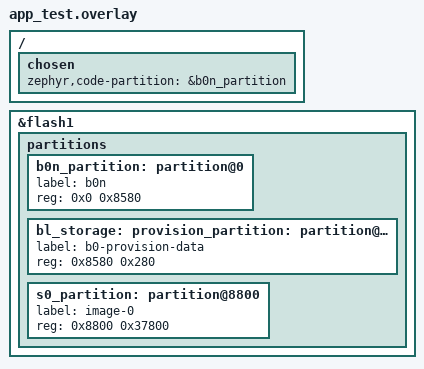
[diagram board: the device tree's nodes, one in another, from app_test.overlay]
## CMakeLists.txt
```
#
# Copyright (c) 2020 Nordic Semiconductor ASA
#
# SPDX-License-Identifier: LicenseRef-Nordic-5-Clause
#

cmake_minimum_required(VERSION 3.20.0)

find_package(Zephyr REQUIRED HINTS $ENV{ZEPHYR_BASE})
project(netboot)

zephyr_library_sources(src/main.c)
```

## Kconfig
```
#
# Copyright (c) 2026 Nordic Semiconductor ASA
#
# SPDX-License-Identifier: LicenseRef-Nordic-5-Clause
#

# minimal-size.conf disables logging, so the logging options are defaults that apply only
# when LOG is enabled.
if LOG

choice LOG_MODE
	depends on !LOG_FRONTEND_ONLY
	default LOG_MODE_MINIMAL
endchoice

configdefault LOG_DEFAULT_LEVEL
	default 0

if SECURE_BOOT_VALIDATION

choice SECURE_BOOT_VALIDATION_LOG_LEVEL_CHOICE
	default SECURE_BOOT_VALIDATION_LOG_LEVEL_INF
endchoice

endif # SECURE_BOOT_VALIDATION

endif # LOG

source "Kconfig.zephyr"
```

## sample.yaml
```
sample:
  name: Network core bootloader sample
  description: Network core bootloader sample for nRF5340
tests:
  sample.nrf5340.netboot:
    sysbuild: true
    build_only: true
    integration_platforms:
      - nrf5340dk/nrf5340/cpunet
    platform_allow:
      - nrf5340dk/nrf5340/cpunet
    # These used to live in prj.conf, but minimal-size.conf sets CONFIG_LOG=n,
    # so they were only ever effective in this scenario.
    extra_configs:
      - CONFIG_SECURE_BOOT_VALIDATION_LOG_LEVEL_INF=y
      - CONFIG_LOG_MODE_MINIMAL=y
      - CONFIG_LOG_DEFAULT_LEVEL=0
    extra_args:
      - DTC_OVERLAY_FILE="test.overlay"
    tags:
      - ci_build
      - sysbuild
      - ci_samples_nrf5340
  sample.nrf5340.netboot.minimal_size:
    sysbuild: true
    build_only: true
    extra_args:
      - DTC_OVERLAY_FILE="test.overlay"
      - EXTRA_CONF_FILE="minimal-size.conf"
    integration_platforms:
      - nrf5340dk/nrf5340/cpunet
    platform_allow:
      - nrf5340dk/nrf5340/cpunet
    tags:
      - ci_build
      - sysbuild
      - ci_samples_nrf5340
```

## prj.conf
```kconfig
#
# Copyright (c) 2020 Nordic Semiconductor ASA
#
# SPDX-License-Identifier: LicenseRef-Nordic-5-Clause
#
CONFIG_NCS_SAMPLES_DEFAULTS=y

CONFIG_IS_SECURE_BOOTLOADER=y
CONFIG_MULTITHREADING=n
CONFIG_GPIO=n
CONFIG_ARM_MPU=n
CONFIG_TICKLESS_KERNEL=n
CONFIG_ERRNO=n
CONFIG_SYS_CLOCK_EXISTS=y
CONFIG_FPROTECT=y
CONFIG_FW_INFO=y
CONFIG_FW_INFO_INVALIDATE_API=n
CONFIG_SECURE_BOOT_CRYPTO=y
CONFIG_SECURE_BOOT_VALIDATION=y
# Ineffective here: unsatisfied dependency LOG in the minimal size build, where minimal-size.conf
# disables it; moved to Kconfig as a default that applies when LOG is enabled.
# CONFIG_SECURE_BOOT_VALIDATION_LOG_LEVEL_INF=y
CONFIG_SECURE_BOOT_STORAGE=y
CONFIG_PCD_NET=y
CONFIG_FLASH=y
CONFIG_FLASH_PAGE_LAYOUT=y
CONFIG_LOG=y
# Ineffective here: unsatisfied dependency LOG in the minimal size build, where minimal-size.conf
# disables it; moved to Kconfig as a default that applies when LOG is enabled.
# CONFIG_LOG_MODE_MINIMAL=y
# Ineffective here: unsatisfied dependency LOG in the minimal size build, where minimal-size.conf
# disables it; moved to Kconfig as a default that applies when LOG is enabled.
# CONFIG_LOG_DEFAULT_LEVEL=0

# To build with a minimal configuration, use the overlay file
# '-DCONF_FILE=minimal-size.conf'
```

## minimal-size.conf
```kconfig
#
# Copyright (c) 2020 Nordic Semiconductor ASA
#
# SPDX-License-Identifier: LicenseRef-Nordic-5-Clause
#

# To reduce size, turn off debug configs
CONFIG_NCS_SAMPLES_DEFAULTS=n
CONFIG_LOG=n
CONFIG_BOOT_BANNER=n
CONFIG_NCS_BOOT_BANNER=n
CONFIG_PRINTK=n
CONFIG_CONSOLE=n
CONFIG_UART_CONSOLE=n
CONFIG_SERIAL=n
CONFIG_ASSERT=n
CONFIG_NRF_RTC_TIMER=n
CONFIG_RESET_ON_FATAL_ERROR=n
CONFIG_REBOOT=n
CONFIG_SYS_CLOCK_EXISTS=n
CONFIG_TIMEOUT_64BIT=n
```

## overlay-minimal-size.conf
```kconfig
#
# Copyright (c) 2020 Nordic Semiconductor ASA
#
# SPDX-License-Identifier: LicenseRef-Nordic-5-Clause
#

# To reduce size, turn off debug configs, and enable minimal partition size
CONFIG_NETBOOT_MIN_PARTITION_SIZE=y
CONFIG_NCS_SAMPLES_DEFAULTS=n
CONFIG_LOG=n
CONFIG_BOOT_BANNER=n
CONFIG_NCS_BOOT_BANNER=n
CONFIG_PRINTK=n
CONFIG_CONSOLE=n
CONFIG_UART_CONSOLE=n
CONFIG_SERIAL=n
CONFIG_ASSERT=n
CONFIG_NRF_RTC_TIMER=n
CONFIG_RESET_ON_FATAL_ERROR=n
CONFIG_REBOOT=n
CONFIG_SYS_CLOCK_EXISTS=n
CONFIG_TIMEOUT_64BIT=n
```

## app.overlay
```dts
/ {
	chosen {
		zephyr,code-partition = &b0n_partition;
	};
};
```

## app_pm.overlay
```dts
/* Intentionally empty file to be removed when partition manager support is dropped */
```

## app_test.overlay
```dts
/delete-node/ &boot_partition;
/delete-node/ &slot0_partition;
/delete-node/ &slot1_partition;
/delete-node/ &storage_partition;

/ {
	chosen {
		zephyr,code-partition = &b0n_partition;
	};
};

&flash1 {
	partitions {
		b0n_partition: partition@0 {
			label = "b0n";
			reg = <0x0 0x8580>;
		};

		bl_storage: provision_partition: partition@8580 {
			label = "b0-provision-data";
			reg = <0x8580 0x280>;
		};

		s0_partition: partition@8800 {
			label = "image-0";
			reg = <0x8800 0x37800>;
		};
	};
};
```

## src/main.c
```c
/*
 * Copyright (c) 2020 Nordic Semiconductor ASA
 *
 * SPDX-License-Identifier: LicenseRef-Nordic-5-Clause
 */

#include <zephyr/types.h>
#include <zephyr/sys/printk.h>
#include <zephyr/storage/flash_map.h>
#include <fw_info.h>
#include <fprotect.h>
#include <bl_storage.h>
#include <bl_boot.h>
#include <bl_validation.h>
#include <dfu/pcd.h>
#include <zephyr/device.h>
#include <zephyr/devicetree.h>
#ifdef CONFIG_PCD_LOCK_NETCORE_DEBUG
#include <nrfx_nvmc.h>
#endif

#define B0N_ADDRESS PARTITION_ADDRESS(b0n_partition)
#define B0N_SIZE (PARTITION_SIZE(b0n_partition) + PARTITION_SIZE(provision_partition))
#define S0_ADDRESS PARTITION_ADDRESS(s0_partition)
#define S0_SIZE PARTITION_SIZE(s0_partition)

BUILD_ASSERT(PARTITION_ADDRESS(provision_partition) ==
	     (PARTITION_ADDRESS(b0n_partition) + PARTITION_SIZE(b0n_partition)),
	     "`provision` partition must be directly after `b0n` partition.");

/* The flash is locked at flash page granularity */
BUILD_ASSERT((B0N_SIZE % CONFIG_FPROTECT_BLOCK_SIZE) == 0,
	     "B0N_SIZE % CONFIG_FPROTECT_BLOCK_SIZE was not 0. Check the `b0n` partition size.");
BUILD_ASSERT((S0_SIZE % CONFIG_FPROTECT_BLOCK_SIZE) == 0,
	     "S0_SIZE % CONFIG_FPROTECT_BLOCK_SIZE was not 0. Check the `s0` partition size.");

int main(void)
{
	int err;
	const struct device *fdev = DEVICE_DT_GET(DT_CHOSEN(zephyr_flash_controller));

	if (!device_is_ready(fdev)) {
		printk("Flash device not ready\n");
		return 0;
	}

	err = fprotect_area(B0N_ADDRESS, B0N_SIZE);
	if (err) {
		printk("Failed to protect b0n flash, cancel startup\n\r");
		goto failure;
	}

	uint32_t s0_addr = s0_address_read();
	bool valid = false;

	switch (pcd_fw_copy_status_get()) {
#ifdef CONFIG_PCD_LOCK_NETCORE_DEBUG
	case PCD_STATUS_LOCK_DEBUG:
		nrfx_nvmc_word_write((uint32_t)&NRF_UICR_NS->APPROTECT,
				     UICR_APPROTECT_PALL_Protected);
		while (!nrfx_nvmc_write_done_check())
			;

		pcd_done();

		/* Success, waiting to be rebooted */
		while (1)
			;
		CODE_UNREACHABLE;
	break;
#endif

#ifdef CONFIG_PCD_READ_NETCORE_APP_VERSION
	case PCD_STATUS_READ_VERSION:
		err = pcd_find_fw_version();
		if (err < 0) {
			printk("Unable to find valid firmware version %d\n\r", err);
			pcd_fw_copy_invalidate();
		}
		pcd_done();

		/* Success, waiting to be rebooted */
		while (1)
			;
		CODE_UNREACHABLE;
	break;
#endif

	case PCD_STATUS_COPY:
		/* First we validate the data where the PCD CMD tells
		 * us that we can find it.
		 */
		uint32_t update_addr = (uint32_t)pcd_cmd_data_ptr_get();

		valid = bl_validate_firmware(s0_addr, update_addr);
		if (!valid) {
			printk("Unable to find valid firmware inside %p\n\r",
				(void *)update_addr);
			goto failure;
		}

		err = pcd_fw_copy(fdev);
		if (err != 0) {
			printk("Failed to transfer image: %d\n\r", err);
			goto failure;
		}

		/* Note that only the SHA is validated, no signature
		 * check is performed. This because the signature validation
		 * is performed by the application core. This check is only
		 * done to verify that the flash copy operation was successful.
		 */
		valid = bl_validate_firmware(s0_addr, s0_addr);
		if (valid) {
			pcd_done();
		} else {
			printk("Unable to find valid firmware inside %p\n\r",
				(void *)s0_addr);
			goto failure;
		}

		/* Success, waiting to be rebooted */
		while (1)
			;
		CODE_UNREACHABLE;
	break;

	default:
		break;
	}

	err = fprotect_area(S0_ADDRESS, S0_SIZE);
	if (err) {
		printk("Failed to protect app flash: %d\n\r", err);
		goto failure;
	}

	bl_boot(fw_info_find(s0_addr));
	return 0;

failure:
	pcd_fw_copy_invalidate();
	return 0;
}
```
